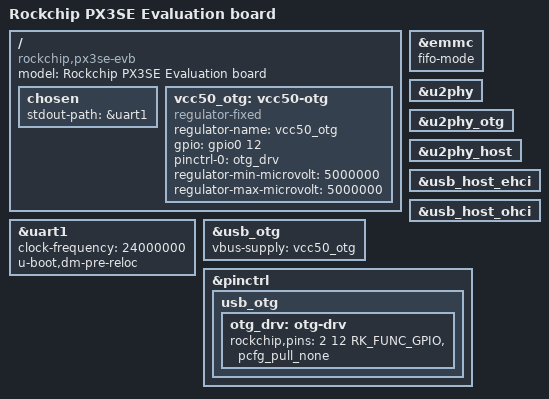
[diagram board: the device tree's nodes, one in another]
/*
 * (C) Copyright 2018 Rockchip Electronics Co., Ltd
 *
 * SPDX-License-Identifier:     GPL-2.0+
 */

/dts-v1/;

#include "rk3128.dtsi"
#include "rk3128-u-boot.dtsi"

/ {
	model = "Rockchip PX3SE Evaluation board";
	compatible = "rockchip,px3se-evb", "rockchip,px3se";

	chosen {
		stdout-path = &uart1;
	};

	vcc50_otg: vcc50-otg {
		compatible = "regulator-fixed";
		regulator-name = "vcc50_otg";
		gpio = <&gpio0 12 GPIO_ACTIVE_HIGH>;
		pinctrl-names = "default";
		pinctrl-0 = <&otg_drv>;
		regulator-min-microvolt = <5000000>;
		regulator-max-microvolt = <5000000>;
	};
};

&emmc {
	fifo-mode;
	status = "okay";
};

&u2phy {
	status = "okay";
};

&u2phy_otg {
	status = "okay";
};

&u2phy_host {
	status = "okay";
};

&uart1 {
	clock-frequency = <24000000>;
	u-boot,dm-pre-reloc;
	status = "okay";
};

&usb_host_ehci {
	status = "okay";
};

&usb_host_ohci {
	status = "okay";
};

&usb_otg {
	vbus-supply = <&vcc50_otg>;
	status = "okay";
};

&pinctrl {
	usb_otg {
		otg_drv: otg-drv {
			rockchip,pins = <2 12 RK_FUNC_GPIO &pcfg_pull_none>;
		};
	};
};
